# NUC100DN_v1 register map
File version: 1.0
Registers are 32-bit, read-write, reset 0x0 unless marked. A register's access mark holds for its fields unless they carry their own. Offsets are from the block's base; [hi:lo] are bit positions; {n}, {i} and the like mark numbered series.

## I2S — I2S Register Map
Base 0x401A0000
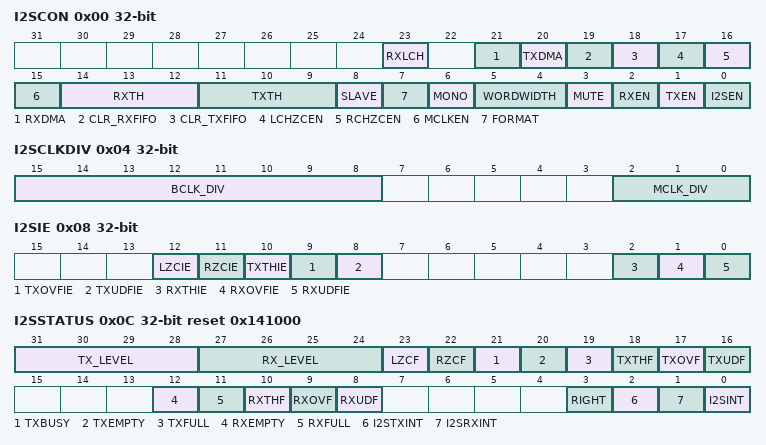
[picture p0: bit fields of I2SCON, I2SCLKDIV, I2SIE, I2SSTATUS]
0x00 I2SCON — I2S Control Register
  [23] RXLCH — Receive Left Channel Enable Bit
    0=Receive right channel data in Mono mode; 1=Receive left channel data in Mono mode
  [21] RXDMA — Enable Receive DMA. When RX DMA is enabled, I2S requests DMA to transfer data from receive FIFO to SRAM if FIFO is not empty.
    0=RX DMA Disabled; 1=RX DMA Enabled
  [20] TXDMA — Enable Transmit DMA. When TX DMA is enabled, I2S request DMA to transfer data from SRAM to transmit FIFO if FIFO is not full.
    0=TX DMA Disabled; 1=TX DMA Enabled
  [19] CLR_RXFIFO — Clear Receive FIFO. Write 1 to clear receive FIFO, internal pointer is reset to FIFO start point, and RXFIFO_LEVEL[3:0] returns 0 and receive FIFO becomes empty. This bit is cleared by hardware automatically. Returns 0 on read.
  [18] CLR_TXFIFO — Clear Transmit FIFO. Write 1 to clear transmit FIFO, internal pointer is reset to FIFO start point, and TXFIFO_LEVEL[3:0] returns to 0 and transmit FIFO becomes empty but data in transmit FIFO is not changed. This bit is cleared by hardware automatically. Returns 0 on read.
  [17] LCHZCEN — Left Channel Zero Cross Detect Enable Bit. If this bit is set to 1, when left channel data sign bit changes or next shift data bits are all 0 then LZCF flag in I2SSTATUS register is set to 1. This function is only available in transmit operation.
    0=Left channel zero cross detect Disabled; 1=Left channel zero cross detect Enabled
  [16] RCHZCEN — Right Channel Zero Cross Detect Enable Bit. If this bit is set to 1, when right channel data sign bit change or next shift data bits are all 0 then RZCF flag in I2SSTATUS register is set to 1. This function is only available in transmit operation.
    0=Right channel zero cross detect Disabled; 1=Right channel zero cross detect Enabled
  [15] MCLKEN — Master Clock Enable Bit. If MCLKEN is set to 1, I2S controller will generate master clock on I2SMCLK pin for external audio devices.
    0=Master clock Disabled; 1=Master clock Enabled
  [14:12] RXTH — Receive FIFO Threshold Level. When received data word(s) in buffer is equal to or higher than threshold level then RXTHF flag is set.
    {v}={v+1} word data in receive FIFO (v=0..7)
  [11:9] TXTH — Transmit FIFO Threshold Level. If remaining data word (32 bits) in transmit FIFO is the same or less than threshold level then TXTHF flag is set.
    0=0 word data in transmit FIFO; 1=1 word data in transmit FIFO; {v}={v} words data in transmit FIFO (v=2..7)
  [8] SLAVE — Slave Mode. I2S can operate as master or slave. For Master mode, I2S_BCLK and I2S_LRCLK pins are output mode and send bit clock from NuMicro NUC100 series to Audio CODEC chip. In Slave mode, I2S_BCLK and I2S_LRCLK pins are input mode and I2S_BCLK and I2S_LRCLK signals are received from outer Audio CODEC chip.
    0=Master mode; 1=Slave mode
  [7] FORMAT — Data Format
    0=I2S data format; 1=MSB justified data format
  [6] MONO — Monaural Data
    0=Data is stereo format; 1=Data is monaural format
  [5:4] WORDWIDTH
    0=data is 8-bit; 1=data is 16-bit; 2=data is 24-bit; 3=data is 32-bit
  [3] MUTE — Transmit Mute Enable Bit
    0=Transmit data is shifted from buffer; 1=Transmit channel zero
  [2] RXEN — Receive Enable Bit
    0=Data receiving Disabled; 1=Data receiving Enabled
  [1] TXEN — Transmit Enable Bit
    0=Data transmit Disabled; 1=Data transmit Enabled
  [0] I2SEN — I2S Controller Enable Bit
    0=I2S Controller Disabled; 1=I2S Controller Enabled
0x04 I2SCLKDIV — I2S Clock Divider Control Register
  [15:8] BCLK_DIV — Bit Clock Divider. The I2S controller will generate bit clock in Master mode. The bit clock rate, F_BCLK, is determined by the following expression.
  [2:0] MCLK_DIV — Master Clock Divider. If MCLKEN is set to 1, I2S controller will generate master clock for external audio devices. The master clock rate, F_MCLK, is determined by the following expressions. F_I2SCLK is the frequency of I2S clock. In general, the master clock rate is 256 times sampling clock rate.
0x08 I2SIE — I2S Interrupt Enable Register
  [all] fields
    0=Interrupt Disabled; 1=Interrupt Enabled
  [12] LZCIE — Left Channel Zero-cross Interrupt Enable Bit. Interrupt occurs if this bit is set to 1 and left channel zero-cross.
  [11] RZCIE — Right Channel Zero-cross Interrupt Enable Bit. Interrupt occurs if this bit is set to 1 and right channel zero-cross.
  [10] TXTHIE — Transmit FIFO Threshold Level Interrupt Enable Bit. Interrupt occurs if this bit is set to 1 and data words in transmit FIFO is less than TXTH[2:0].
  [9] TXOVFIE — Transmit FIFO Overflow Interrupt Enable Bit. Interrupt occurs if this bit is set to 1 and the transmit FIFO overflow flag is set to 1
  [8] TXUDFIE — Transmit FIFO Underflow Interrupt Enable Bit. Interrupt occurs if this bit is set to 1 and the transmit FIFO underflow flag is set to 1.
  [2] RXTHIE — Receive FIFO Threshold Level Interrupt Enable Bit. When data word in receive FIFO is equal to or higher then RXTH[2:0] and the RXTHF bit is set to 1. If RXTHIE bit is enabled, interrupt occurs.
  [1] RXOVFIE — Receive FIFO Overflow Interrupt Enable Bit
  [0] RXUDFIE — Receive FIFO Underflow Interrupt Enable Bit. If software read receive FIFO when it is empty then RXUDF flag in I2SSTATUS register is set to 1.
0x0C I2SSTATUS reset 0x141000
  [31:28] TX_LEVEL — Transmit FIFO Level. These bits indicate word number in transmit FIFO
    0=No data; 1=1 word in transmit FIFO; 8=8 words in transmit FIFO
  [27:24] RX_LEVEL — Receive FIFO Level. These bits indicate word number in receive FIFO
    0=No data; 1=1 word in receive FIFO; 8=8 words in receive FIFO
  [23] LZCF — Left Channel Zero-cross Flag. It indicates left channel next sample data sign bit is changed or all data bits are 0. Note: This bit can be cleared by writing '1' to it.
    0=No zero-cross; 1=Left channel zero-cross is detected
  [22] RZCF — Right Channel Zero-cross Flag. It indicates right channel next sample data sign bit is changed or all data bits are 0. Note: This bit can be cleared by writing '1' to it.
    0=No zero-cross; 1=Right channel zero-cross is detected
  [21] TXBUSY ro — Transmit Busy (Read Only). This bit is cleared to 0 when all data in transmit FIFO and shift buffer is shifted out. And set to 1 when 1st data is load to shift buffer.
    0=Transmit shift buffer is empty; 1=Transmit shift buffer is busy
  [20] TXEMPTY ro — Transmit FIFO Empty (Read Only). This bit reflects data word number in transmit FIFO is 0
    0=Not empty; 1=Empty
  [19] TXFULL ro — Transmit FIFO Full (Read Only). This bit reflects data word number in transmit FIFO is 8
    0=Not full; 1=Full
  [18] TXTHF ro — Transmit FIFO Threshold Flag (Read Only). When data word(s) in transmit FIFO is equal to or lower than threshold value set in TXTH[2:0] the TXTHF bit becomes to 1. It keeps at 1 till TXFIFO_LEVEL[3:0] is higher than TXTH[1:0] after software writes TXFIFO register.
    0=Data word(s) in FIFO is higher than threshold level; 1=Data word(s) in FIFO is equal to or lower than threshold level
  [17] TXOVF — Transmit FIFO Overflow Flag. This bit will be set to 1 if writes data to transmit FIFO when transmit FIFO is full. Note: This bit can be cleared by writing '1' to it.
    0=No overflow; 1=Overflow
  [16] TXUDF — Transmit FIFO Underflow Flag. When transmit FIFO is empty and shift logic hardware read data from transmit FIFO causes this set to 1. Note: This bit can be cleared by writing '1' to it.
    0=No underflow; 1=Underflow
  [12] RXEMPTY ro — Receive FIFO Empty (Read Only). This bit reflects data words number in receive FIFO is 0
    0=Not empty; 1=Empty
  [11] RXFULL ro — Receive FIFO Full (Read Only). This bit reflects data words number in receive FIFO is 8
    0=Not full; 1=Full
  [10] RXTHF ro — Receive FIFO Threshold Flag (Read Only). When data word(s) in receive FIFO is equal to or higher than threshold value set in RXTH[2:0] the RXTHF bit becomes to 1. It keeps at 1 till RXFIFO_LEVEL[3:0] is less than RXTH[1:0] after software read RXFIFO register.
    0=Data word(s) in FIFO is lower than threshold level; 1=Data word(s) in FIFO is equal to or higher than threshold level
  [9] RXOVF — Receive FIFO Overflow Flag. When receive FIFO is full and receive hardware attempt to write data into receive FIFO then this bit is set to 1, data in 1st buffer is overwrote. Note: This bit can be cleared by writing '1' to it.
    0=No overflow; 1=Overflow
  [8] RXUDF — Receive FIFO Underflow Flag. Read receive FIFO when it is empty, this bit set to 1 indicate underflow occurs. Note: This bit can be cleared by writing '1' to it.
    0=No underflow; 1=Underflow
  [3] RIGHT ro — Right Channel (Read Only). This bit indicates current transmit data is belong to right channel
    0=Left channel; 1=Right channel
  [2] I2STXINT ro — I2S Transmit Interrupt (Read Only)
    0=No transmit interrupt; 1=Transmit interrupt
  [1] I2SRXINT ro — I2S Receive Interrupt (Read Only)
    0=No receive interrupt; 1=Receive interrupt
  [0] I2SINT ro — I2S Interrupt Flag (Read Only). It is wire-OR of I2STXINT and I2SRXINT bits.
    0=No I2S interrupt; 1=I2S interrupt
0x10 I2STXFIFO wo — I2S Transmit FIFO Register
  [31:0] TXFIFO — Transmit FIFO Register. I2S contains 8 words (8x32 bits) data buffer for data transmit. Write data to this register to prepare data for transmit. The remaining word number is indicated by TX_LEVEL[3:0] in I2SSTATUS register
0x14 I2SRXFIFO ro — I2S Receive FIFO Register
  [31:0] RXFIFO — Receive FIFO Register. I2S contains 8 words (8x32 bits) data buffer for data receive. Read this register to get data in FIFO. The remaining data word number is indicated by RX_LEVEL[3:0] in I2SSTATUS register.
